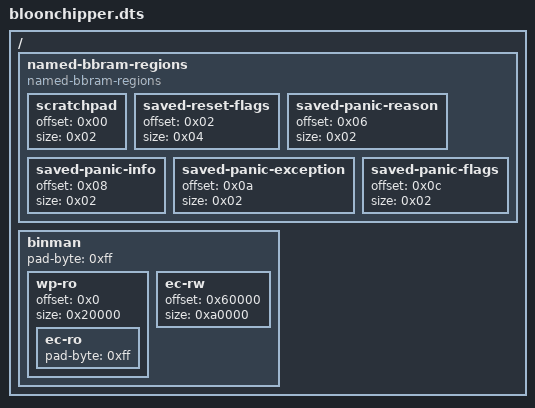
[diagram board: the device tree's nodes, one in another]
/* Copyright 2023 The ChromiumOS Authors.
 * Use of this source code is governed by a BSD-style license that can be
 * found in the LICENSE file.
 */

#include "soc.dtsi"
#include "gpio.dtsi"
#include "rwsig.dtsi"

/ {

	named-bbram-regions {
		compatible = "named-bbram-regions";

		scratchpad {
			offset = <0x00>;
			size = <0x02>;
		};
		saved-reset-flags {
			offset = <0x02>;
			size = <0x04>;
		};
		saved-panic-reason {
			offset = <0x06>;
			size = <0x02>;
		};
		saved-panic-info {
			offset = <0x08>;
			size = <0x02>;
		};
		saved-panic-exception {
			offset = <0x0a>;
			size = <0x02>;
		};
		saved-panic-flags {
			offset = <0x0c>;
			size = <0x02>;
		};
	};

	binman {
		/* First 5 sectors (4 x 16KB, 1 x 64KB) used for RO */
		wp-ro {
			offset = <0x0>;
			size = <0x20000>;
			ec-ro {
				pad-byte = <0xff>;
			};
		};

		/* Two sectors used for rollback (128KB each) */

		/* Remaining 5 sectors (128KB each) used for RW */
		ec-rw {
			offset = <0x60000>;
			size = <0xa0000>;
		};
		pad-byte = <0xff>;
	};
};
